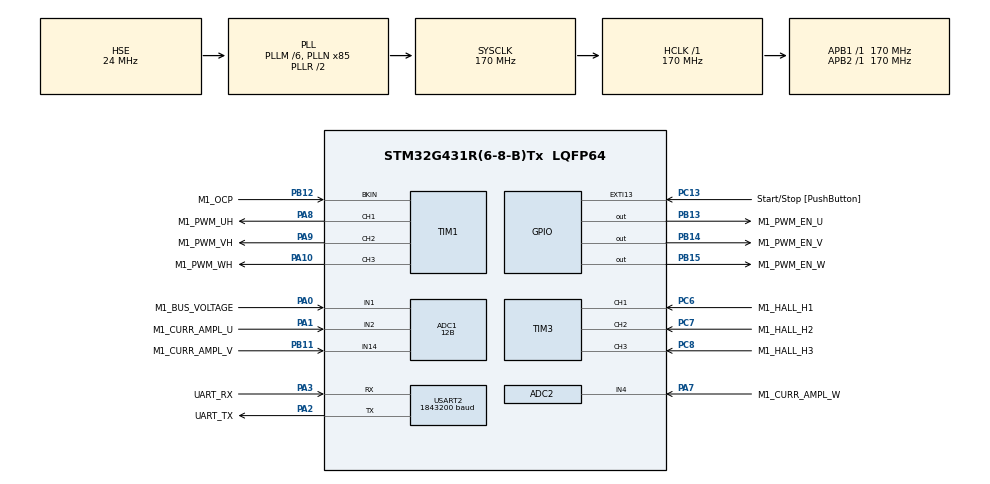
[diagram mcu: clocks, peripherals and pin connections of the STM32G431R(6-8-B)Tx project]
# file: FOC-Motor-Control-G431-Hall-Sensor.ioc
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ADC1.Channel-1\#ChannelRegularConversion=ADC_CHANNEL_1
ADC1.ClockPrescaler=ADC_CLOCK_ASYNC_DIV1
ADC1.ContinuousConvMode=DISABLE
ADC1.DMAContinuousRequests=DISABLE
ADC1.DataAlign=ADC_DATAALIGN_LEFT
ADC1.DiscontinuousConvMode=DISABLE
ADC1.EOCSelection=ADC_EOC_SINGLE_CONV
ADC1.EnableAnalogWatchDog1=false
ADC1.EnableAnalogWatchDog2=false
ADC1.EnableAnalogWatchDog3=false
ADC1.EnableInjectedConversion=ENABLE
ADC1.EnableRegularConversion=ENABLE
ADC1.ExternalTrigConv=ADC_SOFTWARE_START
ADC1.ExternalTrigConvEdge=ADC_EXTERNALTRIGCONVEDGE_NONE
ADC1.ExternalTrigInjecConv=ADC_EXTERNALTRIGINJEC_T1_TRGO
ADC1.ExternalTrigInjecConvEdge=ADC_EXTERNALTRIGINJECCONV_EDGE_RISING
ADC1.InjNumberOfConversion=2
ADC1.InjectedChannel-1\#ChannelInjectedConversion=ADC_CHANNEL_2
ADC1.InjectedChannel-2\#ChannelInjectedConversion=ADC_CHANNEL_14
ADC1.InjectedConvMode=None
ADC1.InjectedOffset-1\#ChannelInjectedConversion=0
ADC1.InjectedOffset-2\#ChannelInjectedConversion=0
ADC1.InjectedOffsetNumber-1\#ChannelInjectedConversion=ADC_OFFSET_NONE
ADC1.InjectedOffsetNumber-2\#ChannelInjectedConversion=ADC_OFFSET_NONE
ADC1.InjectedRank-1\#ChannelInjectedConversion=1
ADC1.InjectedRank-2\#ChannelInjectedConversion=2
ADC1.InjectedSamplingTime-1\#ChannelInjectedConversion=ADC_SAMPLETIME_6CYCLES_5
ADC1.InjectedSamplingTime-2\#ChannelInjectedConversion=ADC_SAMPLETIME_6CYCLES_5
ADC1.LowPowerAutoWait=DISABLE
ADC1.NbrOfConversion=1
ADC1.NbrOfConversionFlag=1
ADC1.Offset-1\#ChannelRegularConversion=0
ADC1.OffsetNumber-1\#ChannelRegularConversion=ADC_OFFSET_NONE
ADC1.Overrun=ADC_OVR_DATA_PRESERVED
ADC1.Rank-1\#ChannelRegularConversion=1
ADC1.Resolution=ADC_RESOLUTION_12B
ADC1.SamplingTime-1\#ChannelRegularConversion=ADC_SAMPLETIME_47CYCLES_5
ADC1.ScanConvMode=ADC_SCAN_ENABLE
ADC1.master=1
ADC2.ClockPrescaler=ADC_CLOCK_ASYNC_DIV1
ADC2.ContinuousConvMode=DISABLE
ADC2.DMAContinuousRequests=DISABLE
ADC2.DataAlign=ADC_DATAALIGN_LEFT
ADC2.DiscontinuousConvMode=DISABLE
ADC2.EOCSelection=ADC_EOC_SINGLE_CONV
ADC2.EnableAnalogWatchDog1=false
ADC2.EnableAnalogWatchDog2=false
ADC2.EnableAnalogWatchDog3=false
ADC2.EnableInjectedConversion=ENABLE
ADC2.EnableRegularConversion=DISABLE
ADC2.ExternalTrigInjecConv=ADC_EXTERNALTRIGINJEC_T1_TRGO
ADC2.ExternalTrigInjecConvEdge=ADC_EXTERNALTRIGINJECCONV_EDGE_RISING
ADC2.InjNumberOfConversion=2
ADC2.InjectedChannel-1\#ChannelInjectedConversion=ADC_CHANNEL_14
ADC2.InjectedChannel-2\#ChannelInjectedConversion=ADC_CHANNEL_4
ADC2.InjectedConvMode=None
ADC2.InjectedOffset-1\#ChannelInjectedConversion=0
ADC2.InjectedOffset-2\#ChannelInjectedConversion=0
ADC2.InjectedOffsetNumber-1\#ChannelInjectedConversion=ADC_OFFSET_NONE
ADC2.InjectedOffsetNumber-2\#ChannelInjectedConversion=ADC_OFFSET_NONE
ADC2.InjectedRank-1\#ChannelInjectedConversion=1
ADC2.InjectedRank-2\#ChannelInjectedConversion=2
ADC2.InjectedSamplingTime-1\#ChannelInjectedConversion=ADC_SAMPLETIME_6CYCLES_5
ADC2.InjectedSamplingTime-2\#ChannelInjectedConversion=ADC_SAMPLETIME_6CYCLES_5
ADC2.LowPowerAutoWait=DISABLE
ADC2.Overrun=ADC_OVR_DATA_PRESERVED
ADC2.Resolution=ADC_RESOLUTION_12B
ADC2.ScanConvMode=ADC_SCAN_ENABLE
ADC2.master=1
Dma.Request0=USART2_RX
Dma.Request1=USART2_TX
Dma.USART2_RX.0.Direction=DMA_PERIPH_TO_MEMORY
Dma.USART2_RX.0.EventEnable=DISABLE
Dma.USART2_RX.0.Instance=DMA1_Channel1
Dma.USART2_RX.0.MemDataAlignment=DMA_MDATAALIGN_BYTE
Dma.USART2_RX.0.MemInc=DMA_MINC_ENABLE
Dma.USART2_RX.0.Mode=DMA_NORMAL
Dma.USART2_RX.0.PeriphDataAlignment=DMA_PDATAALIGN_BYTE
Dma.USART2_RX.0.PeriphInc=DMA_PINC_DISABLE
Dma.USART2_RX.0.Polarity=HAL_DMAMUX_REQ_GEN_RISING
Dma.USART2_RX.0.Priority=DMA_PRIORITY_LOW
Dma.USART2_RX.0.RequestNumber=1
Dma.USART2_RX.0.SignalID=NONE
Dma.USART2_RX.0.SyncEnable=DISABLE
Dma.USART2_RX.0.SyncPolarity=HAL_DMAMUX_SYNC_NO_EVENT
Dma.USART2_RX.0.SyncRequestNumber=1
Dma.USART2_RX.0.SyncSignalID=NONE
Dma.USART2_TX.1.Direction=DMA_MEMORY_TO_PERIPH
Dma.USART2_TX.1.EventEnable=DISABLE
Dma.USART2_TX.1.Instance=DMA1_Channel2
Dma.USART2_TX.1.MemDataAlignment=DMA_MDATAALIGN_BYTE
Dma.USART2_TX.1.MemInc=DMA_MINC_ENABLE
Dma.USART2_TX.1.Mode=DMA_NORMAL
Dma.USART2_TX.1.PeriphDataAlignment=DMA_PDATAALIGN_BYTE
Dma.USART2_TX.1.PeriphInc=DMA_PINC_DISABLE
Dma.USART2_TX.1.Polarity=HAL_DMAMUX_REQ_GEN_RISING
Dma.USART2_TX.1.Priority=DMA_PRIORITY_LOW
Dma.USART2_TX.1.RequestNumber=1
Dma.USART2_TX.1.SignalID=NONE
Dma.USART2_TX.1.SyncEnable=DISABLE
Dma.USART2_TX.1.SyncPolarity=HAL_DMAMUX_SYNC_NO_EVENT
Dma.USART2_TX.1.SyncRequestNumber=1
Dma.USART2_TX.1.SyncSignalID=NONE
ExtraMW=MotorControl
ExtraMW.MotorControl.Config=MotorControl
ExtraMW.MotorControl.Mode=MotorControl
ExtraMW.MotorControl.Root=MCSDK_v6.1.2-Full/MotorControl
ExtraMW.MotorControl.Template=templates
Mcu.Family=STM32G4
Mcu.Name=STM32G431R(6-8-B)Tx
Mcu.Package=LQFP64
MotorControl.ADC_1_PERIPH=ADC1
MotorControl.ADC_2_PERIPH=ADC2
MotorControl.ADC_AHBPERIPH=RCC_AHBPeriph_ADC12
MotorControl.ADC_CLOCK_WB_DIV=1
MotorControl.ADC_PERIPH=ADC1
MotorControl.ADC_REFERENCE_VOLTAGE=3.3
MotorControl.AMPLIFICATION_GAIN=1.53
MotorControl.ANGC={0,0,0,0,0,0,0,0}
MotorControl.BKIN1_FILTER=3
MotorControl.BKIN2_FILTER=0
MotorControl.BKIN2_MODE=NONE
MotorControl.BKIN_MODE=EXT_MODE
MotorControl.BOARD=NUCLEO-G431RB
MotorControl.BUS_VOLTAGE_READING=true
MotorControl.CCMRAM_ENABLED=false
MotorControl.CLOCK_FREQUENCY=CPU_CLK_170_MHZ
MotorControl.CLOCK_SOURCE=EXTERNAL
MotorControl.CONSTANT1_D=1020
MotorControl.CONSTANT1_Q=1020
MotorControl.CONSTANT2_QD=10990
MotorControl.CPU_CLK_170_MHZ=true
MotorControl.CTLBOARD_NAME=NUCLEO-G431RB
MotorControl.CUBE_MX_VER=6.8.0
MotorControl.CURRENT_READING_TOPOLOGY=THREE_SHUNT_INDEPENDENT_RESOURCES
MotorControl.CURR_SAMPLING_TIME=6
MotorControl.DAC_FUNCTIONALITY=false
MotorControl.DC_CURRENT_RS_MEAS=1.54
MotorControl.DEFAULT_CONTROL_MODE=STC_SPEED_MODE
MotorControl.DEFAULT_FLUX_COMPONENT=0
MotorControl.DEFAULT_TARGET_SPEED_RPM=1000
MotorControl.DEFAULT_TORQUE_COMPONENT=0
MotorControl.DISCONTINUOUS_PWM=false
MotorControl.DRIVES_NUMBER_SELECTION=SINGLEDRIVE
MotorControl.DRIVE_TYPE=FOC
MotorControl.EMERGENCY2_STOP_GPIO_PIN=LL_GPIO_PIN_12
MotorControl.EMERGENCY2_STOP_GPIO_PORT=GPIOB
MotorControl.EMERGENCY_STOP_GPIO_PIN=LL_GPIO_PIN_12
MotorControl.EMERGENCY_STOP_GPIO_PORT=GPIOB
MotorControl.ENCODER_AVAILABLE=false
MotorControl.ENCODER_PPR=400
MotorControl.EXT_CLK_24_MHZ=true
MotorControl.EXT_CLOCK_FREQUENCY=EXT_CLK_24_MHZ
MotorControl.FEEDBACK_NET_FILTERING=false
MotorControl.FEED_FORWARD_CURRENT_REG_ENABLING=false
MotorControl.FLUX_WEAKENING_ENABLING=false
MotorControl.FW_KIDIV=32768
MotorControl.FW_KI_GAIN=5000
MotorControl.FW_KPDIV=32768
MotorControl.FW_KP_GAIN=3000
MotorControl.FW_VOLTAGE_REF=985
MotorControl.H1_GPIO_PIN=LL_GPIO_PIN_6
MotorControl.H1_GPIO_PORT=GPIOC
MotorControl.H2_GPIO_PIN=LL_GPIO_PIN_7
MotorControl.H2_GPIO_PORT=GPIOC
MotorControl.H3_GPIO_PIN=LL_GPIO_PIN_8
MotorControl.H3_GPIO_PORT=GPIOC
MotorControl.HALL_AVERAGING_FIFO_DEPTH=16
MotorControl.HALL_ICx_FILTER=119
MotorControl.HALL_MTPA=false
MotorControl.HALL_PHASE_SHIFT=240
MotorControl.HALL_SENSORS=true
MotorControl.HALL_SENSORS_AVAILABLE=true
MotorControl.HALL_SENSORS_PLACEMENT=DEGREES_120
MotorControl.HALL_TIMER_SELECTION=ENC_TIM3
MotorControl.HIGH_SIDE_IDLE_STATE=false
MotorControl.HWV_CS=ThreeShunt_AmplifiedCurrents
MotorControl.HWV_OCP=OnPowerStageOCP
MotorControl.HWV_PWM=DrivingHighSidesAndThreeEnables
MotorControl.HW_COMPLEMENTED_LOW_SIDE=true
MotorControl.HW_DEAD_TIME_NS=550
MotorControl.ID_DEMAG=-15370
MotorControl.IPs=CORDIC,NVIC,RCC,SYS,MotorControl,TIM1,ADC1,ADC2,TIM3,USART2,DMA
MotorControl.IQMAX=15370
MotorControl.LDLQ_RATIO=1.000
MotorControl.LOW_SIDE_IDLE_STATE=false
MotorControl.LOW_SIDE_SIGNALS_ENABLING=ES_GPIO
MotorControl.LS=0.00001
MotorControl.M1_CS_ADC_NUM=2
MotorControl.M1_CS_ADC_PHASE_SHARED=V
MotorControl.M1_CS_ADC_U=ADC1
MotorControl.M1_CS_ADC_W=ADC2
MotorControl.M1_CS_CHANNEL_SHARED=14
MotorControl.M1_CS_CHANNEL_U=2
MotorControl.M1_CS_CHANNEL_V=14
MotorControl.M1_CS_CHANNEL_W=4
MotorControl.M1_CURRENT_AMPLIFICATION_TOPO=EXTERNAL
MotorControl.M1_CURRENT_PROTECTION_DESTINATION=TIM_BKIN
MotorControl.M1_CURRENT_PROTECTION_TOPOLOGY=EXTERNAL
MotorControl.M1_CURRENT_SENSING_TOPO=THREE_SHUNT
MotorControl.M1_DBG_OPEN_LOOP_ENABLE=false
MotorControl.M1_ICL_ENABLED=false
MotorControl.M1_OVP_THRESHOLD_HIGH=27
MotorControl.M1_POTENTIOMETER_ENABLE=false
MotorControl.M1_PWM_CHARGE_BOOT_CAP_DUTY_CYCLES=0.000
MotorControl.M1_PWM_CHARGE_BOOT_CAP_MS=10
MotorControl.M1_PWM_DRIVER_PN=Driver or IGBT or MOSFET Part Number
MotorControl.M1_SS_MEAS_ERRORS_BEFORE_FAULTS=3
MotorControl.MAX_APPLICATION_SPEED=7986
MotorControl.MAX_MODULATION_100_PER_CENT=true
MotorControl.MAX_MODULATION_INDEX=MAX_MODULATION_100_PER_CENT
MotorControl.MAX_READABLE_CURRENT=3.272
MotorControl.MCP_ASPEP_OVER_UART=true
MotorControl.MCP_DATALOG_OVER_ASPEP=true
MotorControl.MCP_DATALOG_OVER_UART_A=true
MotorControl.MCP_DATALOG_OVER_UART_A_SIGNALS=10
MotorControl.MCP_DATALOG_PAYLOAD_MAX_UART_A=2048
MotorControl.MCP_DATALOG_USED=true
MotorControl.MCP_DMACH_RX_UART_A=1
MotorControl.MCP_DMACH_TX_UART_A=2
MotorControl.MCP_DMA_RX_UART_A=DMA1
MotorControl.MCP_DMA_TX_UART_A=DMA1
MotorControl.MCP_IRQ_HANDLER_DMA_RX_UART_A=DMA1_Channel1_IRQHandler
MotorControl.MCP_IRQ_HANDLER_UART_A=USART2_IRQHandler
MotorControl.MCP_OVER_ASPEP=true
MotorControl.MCP_OVER_STLNK=false
MotorControl.MCP_OVER_UART_A=true
MotorControl.MCP_OVER_UART_B=false
MotorControl.MCP_RX_SYNC_PAYLOAD_MAX=128
MotorControl.MCP_TX_SYNC_PAYLOAD_MAX=128
MotorControl.MCP_UART_SELECTION_A=USART2
MotorControl.MCP_USED=true
MotorControl.MCU=STM32G431RB
MotorControl.MCU_FAMILY=STM32G4
MotorControl.MCU_LINE=STM32G4x1
MotorControl.MCU_NAME=STM32G431R(6-8-B)Tx
MotorControl.MCU_PACKAGE=LQFP64
MotorControl.MCU_TYPE=STM32G431RB
MotorControl.MCU_USERNAME=STM32G431RBTx
MotorControl.MC_WORKBENCH_VERSION=6.1.2
MotorControl.MIN_APPLICATION_SPEED=0
MotorControl.MOTOR_MAX_SPEED_RPM=7986
MotorControl.MOTOR_NAME=Pittman-profiler6.1.2-20
MotorControl.MOTOR_TYPE=PMSM
MotorControl.MOTOR_VOLTAGE_CONSTANT=1.4
MotorControl.MTPA_ENABLING=false
MotorControl.NOMINAL_BUS_VOLTAGE_V=22
MotorControl.NOMINAL_CURRENT=15370
MotorControl.OFST={0,0,0,0,0,0,0,0}
MotorControl.ON_OVER_VOLTAGE=TURN_OFF_PWM
MotorControl.OVERCURR_FEEDBACK_POLARITY=EMSTOP_ACTIVE_LOW
MotorControl.OVERMODULATION=false
MotorControl.OV_VOLTAGE_PROT_ENABLING=true
MotorControl.OV_VOLTAGE_THRESHOLD_V=27
MotorControl.PHASE_UH_GPIO_PIN=LL_GPIO_PIN_8
MotorControl.PHASE_UH_GPIO_PORT=GPIOA
MotorControl.PHASE_UH_POLARITY=H_ACTIVE_HIGH
MotorControl.PHASE_UL_GPIO_PIN=LL_GPIO_PIN_13
MotorControl.PHASE_UL_GPIO_PORT=GPIOB
MotorControl.PHASE_UL_POLARITY=L_ACTIVE_HIGH
MotorControl.PHASE_U_CURR_ADC=ADC1
MotorControl.PHASE_U_CURR_CHANNEL=ADC_CHANNEL_2
MotorControl.PHASE_U_GPIO_PIN=LL_GPIO_PIN_1
MotorControl.PHASE_U_GPIO_PORT=GPIOA
MotorControl.PHASE_VH_GPIO_PIN=LL_GPIO_PIN_9
MotorControl.PHASE_VH_GPIO_PORT=GPIOA
MotorControl.PHASE_VH_POLARITY=H_ACTIVE_HIGH
MotorControl.PHASE_VL_GPIO_PIN=LL_GPIO_PIN_14
MotorControl.PHASE_VL_GPIO_PORT=GPIOB
MotorControl.PHASE_VL_POLARITY=L_ACTIVE_HIGH
MotorControl.PHASE_V_CURR_ADC=ADC1
MotorControl.PHASE_V_CURR_CHANNEL=ADC_CHANNEL_14
MotorControl.PHASE_V_GPIO_PIN=LL_GPIO_PIN_11
MotorControl.PHASE_V_GPIO_PORT=GPIOB
MotorControl.PHASE_V_S_CURR_ADC=ADC2
MotorControl.PHASE_V_S_CURR_CHANNEL=ADC_CHANNEL_14
MotorControl.PHASE_V_S_GPIO_PIN=LL_GPIO_PIN_11
MotorControl.PHASE_V_S_GPIO_PORT=GPIOB
MotorControl.PHASE_WH_GPIO_PIN=LL_GPIO_PIN_10
MotorControl.PHASE_WH_GPIO_PORT=GPIOA
MotorControl.PHASE_WH_POLARITY=H_ACTIVE_HIGH
MotorControl.PHASE_WL_GPIO_PIN=LL_GPIO_PIN_15
MotorControl.PHASE_WL_GPIO_PORT=GPIOB
MotorControl.PHASE_WL_POLARITY=L_ACTIVE_HIGH
MotorControl.PHASE_W_CURR_ADC=ADC2
MotorControl.PHASE_W_CURR_CHANNEL=ADC_CHANNEL_4
MotorControl.PHASE_W_GPIO_PIN=LL_GPIO_PIN_7
MotorControl.PHASE_W_GPIO_PORT=GPIOA
MotorControl.PID_FLUX_KD_DEFAULT=100
MotorControl.PID_FLUX_KI_DEFAULT=216
MotorControl.PID_FLUX_KP_DEFAULT=287
MotorControl.PID_SPEED_KD_DEFAULT=0
MotorControl.PID_SPEED_KI_DEFAULT=304
MotorControl.PID_SPEED_KP_DEFAULT=2286
MotorControl.PID_TORQUE_KD_DEFAULT=100
MotorControl.PID_TORQUE_KI_DEFAULT=216
MotorControl.PID_TORQUE_KP_DEFAULT=287
MotorControl.POLE_PAIR_NUM=4
MotorControl.POSITION_CTRL_ENABLING=false
MotorControl.POTENTIOMETER_READING=false
MotorControl.POWERBOARD_NAME=X-NUCLEO-IHM16M1
MotorControl.PWM_FREQUENCY=16000
MotorControl.PWM_TIMER_SELECTION=PWM_TIM1
MotorControl.REGULATION_EXECUTION_RATE=1
MotorControl.RS=0.12
MotorControl.RSHUNT=0.33
MotorControl.RTOS=NONE
MotorControl.R_BRAKE_SWITCH_OFF_THRES_V=21
MotorControl.SEGDIV=0
MotorControl.SHARED_SIGNAL_ENABLE=false
MotorControl.SINGLEDRIVE=true
MotorControl.SPD_DIFFERENTIAL_TERM_ENABLING=false
MotorControl.SPEED_LOOP_FREQUENCY_HZ=1000
MotorControl.SPEED_SENSOR_SELECTION=HALL_SENSORS
MotorControl.SP_KDDIV=16
MotorControl.SP_KIDIV=16384
MotorControl.SP_KPDIV=64
MotorControl.START_STOP_BTN=true
MotorControl.START_STOP_GPIO_PIN=LL_GPIO_PIN_13
MotorControl.START_STOP_GPIO_PORT=GPIOC
MotorControl.START_STOP_POLARITY=DIN_ACTIVE_LOW
MotorControl.START_STOP_POLARITY_EDGE=GPIO_NOPULL
MotorControl.STM32G431RB=true
MotorControl.SW_DEADTIME_NS=525
MotorControl.SW_OV_CURRENT_PROT_ENABLING=true
MotorControl.TEMPERATURE_READING=false
MotorControl.TFDIFFERENTIAL_TERM_ENABLING=false
MotorControl.TF_KDDIV=8192
MotorControl.TF_KIDIV=16384
MotorControl.TF_KPDIV=16384
MotorControl.THREE_SHUNT_INDEPENDENT_RESOURCES=true
MotorControl.TNOISE_NS=500
MotorControl.TRISE_NS=500
MotorControl.USART_RX_GPIO_PIN=LL_GPIO_PIN_3
MotorControl.USART_RX_GPIO_PORT=GPIOA
MotorControl.USART_SELECTION=USE_USART2
MotorControl.USART_SPEED=1843200
MotorControl.USART_TX_GPIO_PIN=LL_GPIO_PIN_2
MotorControl.USART_TX_GPIO_PORT=GPIOA
MotorControl.USE_3OPAMPS=false
MotorControl.USE_INTERNAL_OPAMP=false
MotorControl.UV_VOLTAGE_PROT_ENABLING=false
MotorControl.VBUS_ADC=ADC1
MotorControl.VBUS_ADC_SAMPLING_TIME=47
MotorControl.VBUS_CHANNEL=ADC_CHANNEL_1
MotorControl.VBUS_GPIO_PIN=LL_GPIO_PIN_0
MotorControl.VBUS_GPIO_PORT=GPIOA
MotorControl.VBUS_PARTITIONING_FACTOR=0.0625
MotorControl.WB_UI_ENCODER_HAS_INDEX_PIN=false
MotorControl.WB_UI_FRICTION=1.6
MotorControl.WB_UI_INERTIA=3.08
MotorControl.WB_UI_MAGNETIC_STRUCTURE=SM-PMSM
MotorControl.WB_UI_MAX_CURRENT=1.535
MotorControl.WB_UI_MAX_NOMINAL_DC_VOLTAGE=22
MotorControl.WB_to_Mx_template_version=22-12-05
MotorControl.WB_to_Mx_version=6.1.0
NVIC.ADC1_2_IRQn=true\:2\:0\:true\:true\:false\:5\:true\:true\:true
NVIC.DMA1_Channel1_IRQn=true\:3\:0\:true\:true\:false\:2\:true\:true\:true
NVIC.EXTI15_10_IRQn=true\:3\:0\:false\:true\:false\:7\:true\:true\:true
NVIC.PriorityGroup=NVIC_PRIORITYGROUP_3
NVIC.TIM1_BRK_TIM15_IRQn=true\:4\:1\:true\:true\:false\:3\:true\:true\:true
NVIC.TIM1_UP_TIM16_IRQn=true\:0\:0\:false\:true\:false\:4\:true\:true\:true
NVIC.TIM3_IRQn=true\:3\:0\:false\:true\:false\:6\:true\:true\:true
NVIC.USART2_IRQn=true\:3\:1\:true\:true\:false\:1\:true\:true\:true
PA0.GPIO_Label=M1_BUS_VOLTAGE
PA0.Mode=IN1-Single-Ended
PA0.Signal=ADC1_IN1
PA1.GPIO_Label=M1_CURR_AMPL_U
PA1.Mode=IN2-Single-Ended
PA1.Signal=ADC1_IN2
PA10.GPIO_Label=M1_PWM_WH
PA10.GPIO_PuPd=GPIO_PULLDOWN
PA10.GPIO_Speed=GPIO_SPEED_FREQ_HIGH
PA10.Signal=S_TIM1_CH3
PA13.GPIO_Label=TMS
PA13.Mode=Serial_Wire
PA13.Signal=SYS_JTMS-SWDIO
PA14.GPIO_Label=TCK
PA14.Mode=Serial_Wire
PA14.Signal=SYS_JTCK-SWCLK
PA2.GPIO_Label=UART_TX
PA2.GPIO_Mode=GPIO_MODE_AF_PP
PA2.GPIO_PuPd=GPIO_NOPULL
PA2.GPIO_Speed=GPIO_SPEED_FREQ_LOW
PA2.Mode=Asynchronous
PA2.Signal=USART2_TX
PA3.GPIO_Label=UART_RX
PA3.GPIO_Mode=GPIO_MODE_AF_PP
PA3.GPIO_PuPd=GPIO_NOPULL
PA3.GPIO_Speed=GPIO_SPEED_FREQ_LOW
PA3.Mode=Asynchronous
PA3.Signal=USART2_RX
PA7.GPIO_Label=M1_CURR_AMPL_W
PA7.Mode=IN4-Single-Ended
PA7.Signal=ADC2_IN4
PA8.GPIO_Label=M1_PWM_UH
PA8.GPIO_PuPd=GPIO_PULLDOWN
PA8.GPIO_Speed=GPIO_SPEED_FREQ_HIGH
PA8.Signal=S_TIM1_CH1
PA9.GPIO_Label=M1_PWM_VH
PA9.GPIO_PuPd=GPIO_PULLDOWN
PA9.GPIO_Speed=GPIO_SPEED_FREQ_HIGH
PA9.Signal=S_TIM1_CH2
PB11.GPIO_Label=M1_CURR_AMPL_V
PB11.Signal=SharedAnalog_PB11
PB12.GPIO_Label=M1_OCP
PB12.GPIO_PuPd=GPIO_PULLUP
PB12.Mode=Activate-Break-Input
PB12.Signal=TIM1_BKIN
PB13.GPIO_Label=M1_PWM_EN_U
PB13.GPIO_PuPd=GPIO_PULLDOWN
PB13.GPIO_Speed=GPIO_SPEED_FREQ_HIGH
PB13.Signal=GPIO_Output
PB14.GPIO_Label=M1_PWM_EN_V
PB14.GPIO_PuPd=GPIO_PULLDOWN
PB14.GPIO_Speed=GPIO_SPEED_FREQ_HIGH
PB14.Signal=GPIO_Output
PB15.GPIO_Label=M1_PWM_EN_W
PB15.GPIO_PuPd=GPIO_PULLDOWN
PB15.GPIO_Speed=GPIO_SPEED_FREQ_HIGH
PB15.Signal=GPIO_Output
PC13.GPIO_Label=Start/Stop [PushButton]
PC13.GPIO_ModeDefaultEXTI=GPIO_MODE_IT_FALLING
PC13.GPIO_PuPd=GPIO_NOPULL
PC13.Signal=GPXTI13
PC6.GPIO_Label=M1_HALL_H1
PC6.GPIO_Speed=GPIO_SPEED_FREQ_HIGH
PC6.Signal=S_TIM3_CH1
PC7.GPIO_Label=M1_HALL_H2
PC7.GPIO_Speed=GPIO_SPEED_FREQ_HIGH
PC7.Signal=S_TIM3_CH2
PC8.GPIO_Label=M1_HALL_H3
PC8.GPIO_Speed=GPIO_SPEED_FREQ_HIGH
PC8.Signal=S_TIM3_CH3
PF0-OSC_IN.Mode=HSE-External-Oscillator
PF0-OSC_IN.Signal=RCC_OSC_IN
PF1-OSC_OUT.Mode=HSE-External-Oscillator
PF1-OSC_OUT.Signal=RCC_OSC_OUT
ProjectManager.HeapSize=0x200
ProjectManager.StackSize=0x400
ProjectManager.TargetToolchain=STM32CubeIDE
RCC.ADC12CLockSelection=RCC_ADC12CLKSOURCE_PLL
RCC.ADC12Freq_Value=42500000
RCC.ADC345Freq_Value=170000000
RCC.AHBFreq_Value=170000000
RCC.APB1Freq_Value=170000000
RCC.APB1TimFreq_Value=170000000
RCC.APB2Freq_Value=170000000
RCC.APB2TimFreq_Value=170000000
RCC.CortexFreq_Value=170000000
RCC.EXTERNAL_CLOCK_VALUE=12288000
RCC.EnbaleCSS=true
RCC.HCLKFreq_Value=170000000
RCC.HSE_VALUE=24000000
RCC.HSI48_VALUE=48000000
RCC.HSI_VALUE=16000000
RCC.LSE_VALUE=32768
RCC.PLLM=RCC_PLLM_DIV6
RCC.PLLN=85
RCC.PLLP=RCC_PLLP_DIV8
RCC.PLLSourceVirtual=RCC_PLLSOURCE_HSE
RCC.SYSCLKFreq_VALUE=170000000
RCC.SYSCLKSource=RCC_SYSCLKSOURCE_PLLCLK
RCC.USBFreq_Value=170000000
RCC.VCOOutputFreq_Value=340000000
SH.S_TIM1_CH1.0=TIM1_CH1,PWM Generation1 CH1
SH.S_TIM1_CH2.0=TIM1_CH2,PWM Generation2 CH2
SH.S_TIM1_CH3.0=TIM1_CH3,PWM Generation3 CH3
SH.S_TIM3_CH1.0=TIM3_CH1,Xored_Inputs_Hall_Sensor_Interface
SH.S_TIM3_CH2.0=TIM3_CH2,Xored_Inputs_Hall_Sensor_Interface
SH.S_TIM3_CH3.0=TIM3_CH3,Xored_Inputs_Hall_Sensor_Interface
SH.SharedAnalog_PB11.0=ADC1_IN14,IN14-Single-Ended
SH.SharedAnalog_PB11.1=ADC2_IN14,IN14-Single-Ended
TIM1.AutoReloadPreload=TIM_AUTORELOAD_PRELOAD_DISABLE
TIM1.AutomaticOutput=TIM_AUTOMATICOUTPUT_DISABLE
TIM1.Break2Filter=0
TIM1.Break2Polarity=TIM_BREAK2POLARITY_HIGH
TIM1.Break2State=TIM_BREAK2_DISABLE
TIM1.BreakFilter=3
TIM1.BreakPolarity=TIM_BREAKPOLARITY_HIGH
TIM1.BreakState=TIM_BREAK_ENABLE
TIM1.Channel=TIM_CHANNEL_4
TIM1.Channel-PWM\ Generation1\ CH1=TIM_CHANNEL_1
TIM1.Channel-PWM\ Generation2\ CH2=TIM_CHANNEL_2
TIM1.Channel-PWM\ Generation3\ CH3=TIM_CHANNEL_3
TIM1.Channel-PWM\ Generation4\ No\ Output=TIM_CHANNEL_4
TIM1.ClearInputSource=TIM_CLEARINPUTSOURCE_NONE
TIM1.ClockDivision=TIM_CLOCKDIVISION_DIV2
TIM1.CounterMode=TIM_COUNTERMODE_CENTERALIGNED1
TIM1.LockLevel=TIM_LOCKLEVEL_1
TIM1.OC1Preload_PWM=ENABLE
TIM1.OC2Preload_PWM=ENABLE
TIM1.OC3Preload_PWM=ENABLE
TIM1.OC4Preload_PWM=ENABLE
TIM1.OCFastMode_PWM=TIM_OCFAST_DISABLE
TIM1.OCIdleState_1=TIM_OCIDLESTATE_RESET
TIM1.OCIdleState_2=TIM_OCIDLESTATE_RESET
TIM1.OCIdleState_3=TIM_OCIDLESTATE_RESET
TIM1.OCIdleState_4=TIM_OCIDLESTATE_RESET
TIM1.OCMode_PWM-PWM\ Generation1\ CH1=TIM_OCMODE_PWM1
TIM1.OCMode_PWM-PWM\ Generation2\ CH2=TIM_OCMODE_PWM1
TIM1.OCMode_PWM-PWM\ Generation3\ CH3=TIM_OCMODE_PWM1
TIM1.OCMode_PWM-PWM\ Generation4\ No\ Output=TIM_OCMODE_PWM2
TIM1.OCPolarity_1=TIM_OCPOLARITY_HIGH
TIM1.OCPolarity_2=TIM_OCPOLARITY_HIGH
TIM1.OCPolarity_3=TIM_OCPOLARITY_HIGH
TIM1.OCPolarity_4=TIM_OCPOLARITY_HIGH
TIM1.OffStateIDLEMode=TIM_OSSI_ENABLE
TIM1.OffStateRunMode=TIM_OSSR_ENABLE
TIM1.PeriodNoDither=((PWM_PERIOD_CYCLES) / 2)
TIM1.Prescaler=((TIM_CLOCK_DIVIDER) - 1)
TIM1.PulseNoDither_1=((PWM_PERIOD_CYCLES) / 4)
TIM1.PulseNoDither_2=((PWM_PERIOD_CYCLES) / 4)
TIM1.PulseNoDither_3=((PWM_PERIOD_CYCLES) / 4)
TIM1.PulseNoDither_4=(((PWM_PERIOD_CYCLES) / 2) - (HTMIN))
TIM1.RepetitionCounter=(REP_COUNTER)
TIM1.SourceBRK2DigInput=TIM_BREAKINPUTSOURCE_DISABLE
TIM1.SourceBRKDigInput=TIM_BREAKINPUTSOURCE_ENABLE
TIM1.SourceBRKDigInputPolarity=TIM_BREAKINPUTSOURCE_POLARITY_LOW
TIM1.TIM_MasterOutputTrigger=TIM_TRGO_OC4REF
TIM1.TIM_MasterOutputTrigger2=TIM_TRGO2_RESET
TIM1.TIM_MasterSlaveMode=TIM_MASTERSLAVEMODE_DISABLE
TIM1.TIM_SlaveMode=TIM_SLAVEMODE_TRIGGER
TIM3.IC1Filter=M1_HALL_IC_FILTER
TIM3.PeriodNoDither=M1_HALL_TIM_PERIOD
USART2.BaudRate=1843200
USART2.VirtualMode-Asynchronous=VM_ASYNC
USART2.WordLength=WORDLENGTH_8B
VP_CORDIC_VS_CORDIC.Mode=CORDIC_Activate
VP_MotorControl_MC_ENABLED.Mode=Enabled
VP_SYS_VS_DBSignals.Mode=DisableDeadBatterySignals
VP_TIM1_VS_ClockSourceITR.Mode=TriggerSource_ITR1
VP_TIM1_VS_ControllerModeTrigger.Mode=Trigger Mode
VP_TIM1_VS_no_output4.Mode=PWM Generation4 No Output
VP_TIM3_VS_ClockSourceINT.Mode=Internal
board=custom

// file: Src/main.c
/* USER CODE BEGIN Header */
/**
  ******************************************************************************
  * @file           : main.c
  * @brief          : Main program body
  ******************************************************************************
  * @attention
  *
  * Copyright (c) 2023 STMicroelectronics.
  * All rights reserved.
  *
  * This software is licensed under terms that can be found in the LICENSE file
  * in the root directory of this software component.
  * If no LICENSE file comes with this software, it is provided AS-IS.
  *
  ******************************************************************************
  */
/* USER CODE END Header */
#include "main.h"

ADC_HandleTypeDef hadc1;
ADC_HandleTypeDef hadc2;

CORDIC_HandleTypeDef hcordic;

TIM_HandleTypeDef htim1;
TIM_HandleTypeDef htim3;

UART_HandleTypeDef huart2;
DMA_HandleTypeDef hdma_usart2_rx;
DMA_HandleTypeDef hdma_usart2_tx;

void SystemClock_Config(void);
static void MX_GPIO_Init(void);
static void MX_DMA_Init(void);
static void MX_ADC1_Init(void);
static void MX_ADC2_Init(void);
static void MX_CORDIC_Init(void);
static void MX_TIM1_Init(void);
static void MX_TIM3_Init(void);
static void MX_USART2_UART_Init(void);
static void MX_NVIC_Init(void);

/* USER CODE BEGIN 0 */
//State_t state_test1;
//State_t state_test2;
//MCI_Handle *pMCIHandle;
/* USER CODE END 0 */

int main(void)
{

  /* MCU Configuration--------------------------------------------------------*/

  /* Reset of all peripherals, Initializes the Flash interface and the Systick. */
  HAL_Init();

  /* Configure the system clock */
  SystemClock_Config();

  /* Initialize all configured peripherals */
  MX_GPIO_Init();
  MX_DMA_Init();
  MX_ADC1_Init();
  MX_ADC2_Init();
  MX_CORDIC_Init();
  MX_TIM1_Init();
  MX_TIM3_Init();
  MX_USART2_UART_Init();
  MX_MotorControl_Init();

  /* Initialize interrupts */
  MX_NVIC_Init();
  /* USER CODE BEGIN 2 */

  //state_test1 = MCI_GetSTMState(pMCIHandle);

  //HAL_Delay(500);
  //MC_ProgramSpeedRampMotor1(400/6, 200);
  //MC_ProgramSpeedRampMotor1(1000/6, 200);
  //MC_StartMotor1();							  // default speed = 1000 RPM
  //HAL_Delay(10000);
  //MC_ProgramSpeedRampMotor1(600/6, 200);
 // MC_ProgramSpeedRampMotor1(1200/6, 200);     // speed parameter unit is 0.1Hz, (1200 RPM/60)*10 = 200 (0.1Hz)
  									          // set speed to 1200 RPM
  //state_test2 = MCI_GetSTMState(pMCIHandle);

//  HAL_Delay(10000);
//  MC_ProgramSpeedRampMotor1(400/6, 1000);
//  HAL_Delay(10000);
//  MC_ProgramSpeedRampMotor1(-400/6, 1000);
//  HAL_Delay(10000);
//  MC_StopMotor1();
  MC_StartMotor1();

  /* USER CODE END 2 */

  /* Infinite loop */
  /* USER CODE BEGIN WHILE */
  while (1)
  {
      // wait for User Button pressed to start or stop motor

	  MC_ProgramSpeedRampMotor1(700/6, 3000);
	  MC_StartMotor1();
	  HAL_Delay(8000);
	  MC_StopMotor1();
	  HAL_Delay(2000);

	  MC_ProgramSpeedRampMotor1(-700/6, 3000);
	  MC_StartMotor1();
	  HAL_Delay(8000);
	  MC_StopMotor1();
	  HAL_Delay(2000);

	  /* USER CODE END WHILE */

  }
}

void SystemClock_Config(void)
{
  RCC_OscInitTypeDef RCC_OscInitStruct = {0};
  RCC_ClkInitTypeDef RCC_ClkInitStruct = {0};

  /** Configure the main internal regulator output voltage
  */
  HAL_PWREx_ControlVoltageScaling(PWR_REGULATOR_VOLTAGE_SCALE1_BOOST);

  /** Initializes the RCC Oscillators according to the specified parameters
  * in the RCC_OscInitTypeDef structure.
  */
  RCC_OscInitStruct.OscillatorType = RCC_OSCILLATORTYPE_HSE;
  RCC_OscInitStruct.HSEState = RCC_HSE_ON;
  RCC_OscInitStruct.PLL.PLLState = RCC_PLL_ON;
  RCC_OscInitStruct.PLL.PLLSource = RCC_PLLSOURCE_HSE;
  RCC_OscInitStruct.PLL.PLLM = RCC_PLLM_DIV6;
  RCC_OscInitStruct.PLL.PLLN = 85;
  RCC_OscInitStruct.PLL.PLLP = RCC_PLLP_DIV8;
  RCC_OscInitStruct.PLL.PLLQ = RCC_PLLQ_DIV2;
  RCC_OscInitStruct.PLL.PLLR = RCC_PLLR_DIV2;
  if (HAL_RCC_OscConfig(&RCC_OscInitStruct) != HAL_OK)
  {
    Error_Handler();
  }

  /** Initializes the CPU, AHB and APB buses clocks
  */
  RCC_ClkInitStruct.ClockType = RCC_CLOCKTYPE_HCLK|RCC_CLOCKTYPE_SYSCLK
                              |RCC_CLOCKTYPE_PCLK1|RCC_CLOCKTYPE_PCLK2;
  RCC_ClkInitStruct.SYSCLKSource = RCC_SYSCLKSOURCE_PLLCLK;
  RCC_ClkInitStruct.AHBCLKDivider = RCC_SYSCLK_DIV1;
  RCC_ClkInitStruct.APB1CLKDivider = RCC_HCLK_DIV1;
  RCC_ClkInitStruct.APB2CLKDivider = RCC_HCLK_DIV1;

  if (HAL_RCC_ClockConfig(&RCC_ClkInitStruct, FLASH_LATENCY_4) != HAL_OK)
  {
    Error_Handler();
  }

  /** Enables the Clock Security System
  */
  HAL_RCC_EnableCSS();
}

/**
  * @brief NVIC Configuration.
  * @retval None
  */
static void MX_NVIC_Init(void)
{
  /* USART2_IRQn interrupt configuration */
  HAL_NVIC_SetPriority(USART2_IRQn, 3, 1);
  HAL_NVIC_EnableIRQ(USART2_IRQn);
  /* DMA1_Channel1_IRQn interrupt configuration */
  HAL_NVIC_SetPriority(DMA1_Channel1_IRQn, 3, 0);
  HAL_NVIC_EnableIRQ(DMA1_Channel1_IRQn);
  /* TIM1_BRK_TIM15_IRQn interrupt configuration */
  HAL_NVIC_SetPriority(TIM1_BRK_TIM15_IRQn, 4, 1);
  HAL_NVIC_EnableIRQ(TIM1_BRK_TIM15_IRQn);
  /* TIM1_UP_TIM16_IRQn interrupt configuration */
  HAL_NVIC_SetPriority(TIM1_UP_TIM16_IRQn, 0, 0);
  HAL_NVIC_EnableIRQ(TIM1_UP_TIM16_IRQn);
  /* ADC1_2_IRQn interrupt configuration */
  HAL_NVIC_SetPriority(ADC1_2_IRQn, 2, 0);
  HAL_NVIC_EnableIRQ(ADC1_2_IRQn);
  /* TIM3_IRQn interrupt configuration */
  HAL_NVIC_SetPriority(TIM3_IRQn, 3, 0);
  HAL_NVIC_EnableIRQ(TIM3_IRQn);
  /* EXTI15_10_IRQn interrupt configuration */
  HAL_NVIC_SetPriority(EXTI15_10_IRQn, 3, 0);
  HAL_NVIC_EnableIRQ(EXTI15_10_IRQn);
}

static void MX_ADC1_Init(void)
{

  ADC_MultiModeTypeDef multimode = {0};
  ADC_InjectionConfTypeDef sConfigInjected = {0};
  ADC_ChannelConfTypeDef sConfig = {0};

  /** Common config
  */
  hadc1.Instance = ADC1;
  hadc1.Init.ClockPrescaler = ADC_CLOCK_ASYNC_DIV1;
  hadc1.Init.Resolution = ADC_RESOLUTION_12B;
  hadc1.Init.DataAlign = ADC_DATAALIGN_LEFT;
  hadc1.Init.GainCompensation = 0;
  hadc1.Init.ScanConvMode = ADC_SCAN_ENABLE;
  hadc1.Init.EOCSelection = ADC_EOC_SINGLE_CONV;
  hadc1.Init.LowPowerAutoWait = DISABLE;
  hadc1.Init.ContinuousConvMode = DISABLE;
  hadc1.Init.NbrOfConversion = 1;
  hadc1.Init.DiscontinuousConvMode = DISABLE;
  hadc1.Init.ExternalTrigConv = ADC_SOFTWARE_START;
  hadc1.Init.ExternalTrigConvEdge = ADC_EXTERNALTRIGCONVEDGE_NONE;		// No external trigger
  hadc1.Init.DMAContinuousRequests = DISABLE;
  hadc1.Init.Overrun = ADC_OVR_DATA_PRESERVED;
  hadc1.Init.OversamplingMode = DISABLE;
  if (HAL_ADC_Init(&hadc1) != HAL_OK)
  {
    Error_Handler();
  }

  /** Configure the ADC multi-mode
  */
  multimode.Mode = ADC_MODE_INDEPENDENT;
  if (HAL_ADCEx_MultiModeConfigChannel(&hadc1, &multimode) != HAL_OK)
  {
    Error_Handler();
  }

  /** Configure Injected Channel
  */
  sConfigInjected.InjectedChannel = ADC_CHANNEL_2;
  sConfigInjected.InjectedRank = ADC_INJECTED_RANK_1;
  sConfigInjected.InjectedSamplingTime = ADC_SAMPLETIME_6CYCLES_5;
  sConfigInjected.InjectedSingleDiff = ADC_SINGLE_ENDED;
  sConfigInjected.InjectedOffsetNumber = ADC_OFFSET_NONE;
  sConfigInjected.InjectedOffset = 0;
  sConfigInjected.InjectedNbrOfConversion = 2;
  sConfigInjected.InjectedDiscontinuousConvMode = DISABLE;
  sConfigInjected.AutoInjectedConv = DISABLE;
  sConfigInjected.QueueInjectedContext = DISABLE;
  sConfigInjected.ExternalTrigInjecConv = ADC_EXTERNALTRIGINJEC_T1_TRGO;		// real trigger
  sConfigInjected.ExternalTrigInjecConvEdge = ADC_EXTERNALTRIGINJECCONV_EDGE_RISING;
  sConfigInjected.InjecOversamplingMode = DISABLE;
  if (HAL_ADCEx_InjectedConfigChannel(&hadc1, &sConfigInjected) != HAL_OK)
  {
    Error_Handler();
  }

  /** Configure Injected Channel
  */
  sConfigInjected.InjectedChannel = ADC_CHANNEL_14;
  sConfigInjected.InjectedRank = ADC_INJECTED_RANK_2;
  if (HAL_ADCEx_InjectedConfigChannel(&hadc1, &sConfigInjected) != HAL_OK)
  {
    Error_Handler();
  }

  /** Configure Regular Channel
  */
  sConfig.Channel = ADC_CHANNEL_1;
  sConfig.Rank = ADC_REGULAR_RANK_1;
  sConfig.SamplingTime = ADC_SAMPLETIME_47CYCLES_5;
  sConfig.SingleDiff = ADC_SINGLE_ENDED;
  sConfig.OffsetNumber = ADC_OFFSET_NONE;
  sConfig.Offset = 0;
  if (HAL_ADC_ConfigChannel(&hadc1, &sConfig) != HAL_OK)
  {
    Error_Handler();
  }

}

static void MX_ADC2_Init(void)
{

  ADC_InjectionConfTypeDef sConfigInjected = {0};

  /** Common config
  */
  hadc2.Instance = ADC2;
  hadc2.Init.ClockPrescaler = ADC_CLOCK_ASYNC_DIV1;
  hadc2.Init.Resolution = ADC_RESOLUTION_12B;
  hadc2.Init.DataAlign = ADC_DATAALIGN_LEFT;
  hadc2.Init.GainCompensation = 0;
  hadc2.Init.ScanConvMode = ADC_SCAN_ENABLE;
  hadc2.Init.EOCSelection = ADC_EOC_SINGLE_CONV;
  hadc2.Init.LowPowerAutoWait = DISABLE;
  hadc2.Init.ContinuousConvMode = DISABLE;
  hadc2.Init.NbrOfConversion = 1;
  hadc2.Init.DiscontinuousConvMode = DISABLE;
  hadc2.Init.DMAContinuousRequests = DISABLE;
  hadc2.Init.Overrun = ADC_OVR_DATA_PRESERVED;
  hadc2.Init.OversamplingMode = DISABLE;
  if (HAL_ADC_Init(&hadc2) != HAL_OK)
  {
    Error_Handler();
  }

  /** Configure Injected Channel
  */
  sConfigInjected.InjectedChannel = ADC_CHANNEL_14;
  sConfigInjected.InjectedRank = ADC_INJECTED_RANK_1;
  sConfigInjected.InjectedSamplingTime = ADC_SAMPLETIME_6CYCLES_5;
  sConfigInjected.InjectedSingleDiff = ADC_SINGLE_ENDED;
  sConfigInjected.InjectedOffsetNumber = ADC_OFFSET_NONE;
  sConfigInjected.InjectedOffset = 0;
  sConfigInjected.InjectedNbrOfConversion = 2;
  sConfigInjected.InjectedDiscontinuousConvMode = DISABLE;
  sConfigInjected.AutoInjectedConv = DISABLE;
  sConfigInjected.QueueInjectedContext = DISABLE;
  sConfigInjected.ExternalTrigInjecConv = ADC_EXTERNALTRIGINJEC_T1_TRGO;
  sConfigInjected.ExternalTrigInjecConvEdge = ADC_EXTERNALTRIGINJECCONV_EDGE_RISING;
  sConfigInjected.InjecOversamplingMode = DISABLE;
  if (HAL_ADCEx_InjectedConfigChannel(&hadc2, &sConfigInjected) != HAL_OK)
  {
    Error_Handler();
  }

  /** Configure Injected Channel
  */
  sConfigInjected.InjectedChannel = ADC_CHANNEL_4;
  sConfigInjected.InjectedRank = ADC_INJECTED_RANK_2;
  if (HAL_ADCEx_InjectedConfigChannel(&hadc2, &sConfigInjected) != HAL_OK)
  {
    Error_Handler();
  }

}

static void MX_CORDIC_Init(void)
{

  hcordic.Instance = CORDIC;
  if (HAL_CORDIC_Init(&hcordic) != HAL_OK)
  {
    Error_Handler();
  }

}

static void MX_TIM1_Init(void)
{

  TIM_SlaveConfigTypeDef sSlaveConfig = {0};
  TIM_MasterConfigTypeDef sMasterConfig = {0};
  TIMEx_BreakInputConfigTypeDef sBreakInputConfig = {0};
  TIM_OC_InitTypeDef sConfigOC = {0};
  TIM_BreakDeadTimeConfigTypeDef sBreakDeadTimeConfig = {0};

  htim1.Instance = TIM1;
  htim1.Init.Prescaler = ((TIM_CLOCK_DIVIDER) - 1);			// 0, Prescaler = 1
  htim1.Init.CounterMode = TIM_COUNTERMODE_CENTERALIGNED1;	// Center-aligned mode 1
  htim1.Init.Period = ((PWM_PERIOD_CYCLES) / 2);			// half because of Center-aligned mode
  htim1.Init.ClockDivision = TIM_CLOCKDIVISION_DIV2;		// tDTS = 2*tCK_INT, dead time, filter
  htim1.Init.RepetitionCounter = (REP_COUNTER);				// 1, FOC execution rate in number of PWM cycles
  htim1.Init.AutoReloadPreload = TIM_AUTORELOAD_PRELOAD_DISABLE;	// TIM1 auto-reload preload is disable
  if (HAL_TIM_Base_Init(&htim1) != HAL_OK)
  {
    Error_Handler();
  }
  if (HAL_TIM_PWM_Init(&htim1) != HAL_OK)
  {
    Error_Handler();
  }
  sSlaveConfig.SlaveMode = TIM_SLAVEMODE_TRIGGER;			// SMS=110: Trigger Mode in SMCR register
  sSlaveConfig.InputTrigger = TIM_TS_ITR1;					// Internal Trigger 1 (tim_itr1)  DO we use it? who connect to it?
  	  	  	  	  	  	  	  	  	  	  	  	  	  	  	// startTimers() trigger TIM1 by TIM2, once TIM1 starts, then trigger this.
  if (HAL_TIM_SlaveConfigSynchro(&htim1, &sSlaveConfig) != HAL_OK)
  {
    Error_Handler();
  }
  sMasterConfig.MasterOutputTrigger = TIM_TRGO_OC4REF;		// OC4REF signal is used as trigger output(TRGO)
  sMasterConfig.MasterOutputTrigger2 = TIM_TRGO2_RESET;		// TIMx_EGR.UG bit is used as trigger output (TRGO2). RESET means not using
  sMasterConfig.MasterSlaveMode = TIM_MASTERSLAVEMODE_DISABLE;	// MSM = 0, no master mode, is slave mode.
  if (HAL_TIMEx_MasterConfigSynchronization(&htim1, &sMasterConfig) != HAL_OK) 		// modify TIM1 CR2 =0x70, SMCR = 0x16
  {
    Error_Handler();
  }
  sBreakInputConfig.Source = TIM_BREAKINPUTSOURCE_BKIN;
  sBreakInputConfig.Enable = TIM_BREAKINPUTSOURCE_ENABLE;
  sBreakInputConfig.Polarity = TIM_BREAKINPUTSOURCE_POLARITY_LOW;
  if (HAL_TIMEx_ConfigBreakInput(&htim1, TIM_BREAKINPUT_BRK, &sBreakInputConfig) != HAL_OK)
  {
    Error_Handler();
  }
  sConfigOC.OCMode = TIM_OCMODE_PWM1;					// OC mode
  sConfigOC.Pulse = ((PWM_PERIOD_CYCLES) / 4);			//
  sConfigOC.OCPolarity = TIM_OCPOLARITY_HIGH;
  sConfigOC.OCNPolarity = TIM_OCNPOLARITY_HIGH;
  sConfigOC.OCFastMode = TIM_OCFAST_DISABLE;
  sConfigOC.OCIdleState = TIM_OCIDLESTATE_RESET;
  sConfigOC.OCNIdleState = TIM_OCNIDLESTATE_RESET;
  if (HAL_TIM_PWM_ConfigChannel(&htim1, &sConfigOC, TIM_CHANNEL_1) != HAL_OK)
  {
    Error_Handler();
  }
  if (HAL_TIM_PWM_ConfigChannel(&htim1, &sConfigOC, TIM_CHANNEL_2) != HAL_OK)
  {
    Error_Handler();
  }
  if (HAL_TIM_PWM_ConfigChannel(&htim1, &sConfigOC, TIM_CHANNEL_3) != HAL_OK)
  {
    Error_Handler();
  }
  sConfigOC.OCMode = TIM_OCMODE_PWM2;					//
  sConfigOC.Pulse = (((PWM_PERIOD_CYCLES) / 2) - (HTMIN));		// trigger the ADC to sample
  if (HAL_TIM_PWM_ConfigChannel(&htim1, &sConfigOC, TIM_CHANNEL_4) != HAL_OK) //
  {
    Error_Handler();
  }
  sBreakDeadTimeConfig.OffStateRunMode = TIM_OSSR_ENABLE;
  sBreakDeadTimeConfig.OffStateIDLEMode = TIM_OSSI_ENABLE;
  sBreakDeadTimeConfig.LockLevel = TIM_LOCKLEVEL_1;
  sBreakDeadTimeConfig.DeadTime = 0;
  sBreakDeadTimeConfig.BreakState = TIM_BREAK_ENABLE;			// do not use break function
  sBreakDeadTimeConfig.BreakPolarity = TIM_BREAKPOLARITY_HIGH;
  sBreakDeadTimeConfig.BreakFilter = 3;
  sBreakDeadTimeConfig.BreakAFMode = TIM_BREAK_AFMODE_INPUT;
  sBreakDeadTimeConfig.Break2State = TIM_BREAK2_DISABLE;
  sBreakDeadTimeConfig.Break2Polarity = TIM_BREAK2POLARITY_HIGH;
  sBreakDeadTimeConfig.Break2Filter = 0;
  sBreakDeadTimeConfig.Break2AFMode = TIM_BREAK_AFMODE_INPUT;
  sBreakDeadTimeConfig.AutomaticOutput = TIM_AUTOMATICOUTPUT_DISABLE;
  if (HAL_TIMEx_ConfigBreakDeadTime(&htim1, &sBreakDeadTimeConfig) != HAL_OK)
  {
    Error_Handler();
  }
  HAL_TIM_MspPostInit(&htim1);

}

static void MX_TIM3_Init(void)
{

  TIM_ClockConfigTypeDef sClockSourceConfig = {0};
  TIM_HallSensor_InitTypeDef sConfig = {0};
  TIM_MasterConfigTypeDef sMasterConfig = {0};

  htim3.Instance = TIM3;
  htim3.Init.Prescaler = 0;
  htim3.Init.CounterMode = TIM_COUNTERMODE_UP;
  htim3.Init.Period = M1_HALL_TIM_PERIOD;
  htim3.Init.ClockDivision = TIM_CLOCKDIVISION_DIV1;
  htim3.Init.AutoReloadPreload = TIM_AUTORELOAD_PRELOAD_DISABLE;
  if (HAL_TIM_Base_Init(&htim3) != HAL_OK)
  {
    Error_Handler();
  }
  sClockSourceConfig.ClockSource = TIM_CLOCKSOURCE_INTERNAL;
  if (HAL_TIM_ConfigClockSource(&htim3, &sClockSourceConfig) != HAL_OK)
  {
    Error_Handler();
  }
  sConfig.IC1Polarity = TIM_ICPOLARITY_RISING;
  sConfig.IC1Prescaler = TIM_ICPSC_DIV1;
  sConfig.IC1Filter = M1_HALL_IC_FILTER;
  sConfig.Commutation_Delay = 0;
  if (HAL_TIMEx_HallSensor_Init(&htim3, &sConfig) != HAL_OK)
  {
    Error_Handler();
  }
  sMasterConfig.MasterOutputTrigger = TIM_TRGO_OC2REF;			// do what?? in next step
  sMasterConfig.MasterSlaveMode = TIM_MASTERSLAVEMODE_DISABLE;	 // MSM = 0, no master mode, is slave mode.
  if (HAL_TIMEx_MasterConfigSynchronization(&htim3, &sMasterConfig) != HAL_OK)
  {
    Error_Handler();
  }

}

static void MX_USART2_UART_Init(void)
{

  huart2.Instance = USART2;
  huart2.Init.BaudRate = 1843200;
  huart2.Init.WordLength = UART_WORDLENGTH_8B;
  huart2.Init.StopBits = UART_STOPBITS_1;
  huart2.Init.Parity = UART_PARITY_NONE;
  huart2.Init.Mode = UART_MODE_TX_RX;
  huart2.Init.HwFlowCtl = UART_HWCONTROL_NONE;
  huart2.Init.OverSampling = UART_OVERSAMPLING_16;
  huart2.Init.OneBitSampling = UART_ONE_BIT_SAMPLE_DISABLE;
  huart2.Init.ClockPrescaler = UART_PRESCALER_DIV1;
  huart2.AdvancedInit.AdvFeatureInit = UART_ADVFEATURE_NO_INIT;
  if (HAL_UART_Init(&huart2) != HAL_OK)
  {
    Error_Handler();
  }
  if (HAL_UARTEx_SetTxFifoThreshold(&huart2, UART_TXFIFO_THRESHOLD_1_8) != HAL_OK)
  {
    Error_Handler();
  }
  if (HAL_UARTEx_SetRxFifoThreshold(&huart2, UART_RXFIFO_THRESHOLD_1_8) != HAL_OK)
  {
    Error_Handler();
  }
  if (HAL_UARTEx_DisableFifoMode(&huart2) != HAL_OK)
  {
    Error_Handler();
  }

}

static void MX_DMA_Init(void)
{

  /* DMA controller clock enable */
  __HAL_RCC_DMAMUX1_CLK_ENABLE();
  __HAL_RCC_DMA1_CLK_ENABLE();

}

static void MX_GPIO_Init(void)
{
  GPIO_InitTypeDef GPIO_InitStruct = {0};

  /* GPIO Ports Clock Enable */
  __HAL_RCC_GPIOC_CLK_ENABLE();
  __HAL_RCC_GPIOF_CLK_ENABLE();
  __HAL_RCC_GPIOA_CLK_ENABLE();
  __HAL_RCC_GPIOB_CLK_ENABLE();

  /*Configure GPIO pin Output Level */
  HAL_GPIO_WritePin(GPIOB, M1_PWM_EN_U_Pin|M1_PWM_EN_V_Pin|M1_PWM_EN_W_Pin, GPIO_PIN_RESET);

  /*Configure GPIO pin : Start_Stop_Pin */
  GPIO_InitStruct.Pin = Start_Stop_Pin;
  GPIO_InitStruct.Mode = GPIO_MODE_IT_FALLING;
  GPIO_InitStruct.Pull = GPIO_NOPULL;
  HAL_GPIO_Init(Start_Stop_GPIO_Port, &GPIO_InitStruct);

  /*Configure GPIO pins : M1_PWM_EN_U_Pin M1_PWM_EN_V_Pin M1_PWM_EN_W_Pin */
  GPIO_InitStruct.Pin = M1_PWM_EN_U_Pin|M1_PWM_EN_V_Pin|M1_PWM_EN_W_Pin;
  GPIO_InitStruct.Mode = GPIO_MODE_OUTPUT_PP;
  GPIO_InitStruct.Pull = GPIO_PULLDOWN;
  GPIO_InitStruct.Speed = GPIO_SPEED_FREQ_HIGH;
  HAL_GPIO_Init(GPIOB, &GPIO_InitStruct);

}

void Error_Handler(void)
{
  __disable_irq();
  while (1)
  {
  }
}
